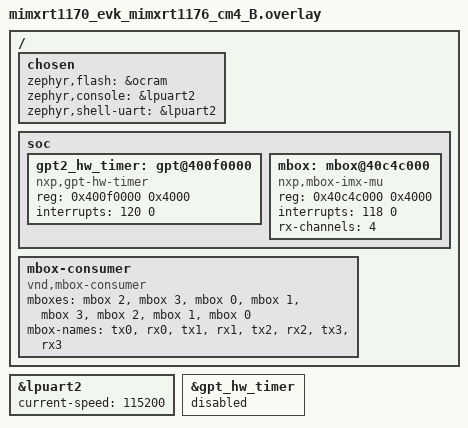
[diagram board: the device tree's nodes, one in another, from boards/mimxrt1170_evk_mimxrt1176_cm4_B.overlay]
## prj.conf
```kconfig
CONFIG_STDOUT_CONSOLE=n
CONFIG_MBOX=y
# CONFIG_NO_OPTIMIZATIONS=y
```

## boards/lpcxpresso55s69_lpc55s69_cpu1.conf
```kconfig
CONFIG_SECOND_CORE_MCUX=y
CONFIG_BUILD_OUTPUT_HEX=y
CONFIG_MBOX_NXP_MAILBOX=y
```

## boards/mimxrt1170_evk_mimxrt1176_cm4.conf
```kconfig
CONFIG_MBOX_NXP_IMX_MU=y
CONFIG_BUILD_OUTPUT_INFO_HEADER=y
CONFIG_BUILD_OUTPUT_HEX=y
CONFIG_SECOND_CORE_MCUX=y
```

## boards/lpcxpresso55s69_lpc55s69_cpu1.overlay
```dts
/*
 * Copyright 2024 NXP
 *
 * SPDX-License-Identifier: Apache-2.0
 */

/ {
	chosen {
		/* Delete ipc chosen property where old IPM mailbox driver bellow is
		 * configured.
		 */
		/delete-property/ zephyr,ipc;
	};

	soc {
		/* Delete IPM Driver node nxp,lpc-mailbox */
		/delete-node/ mailbox@8b000;

		/* Attach MBOX driver to Mailbox Unit */
		mbox:mbox@5008b000 {
			compatible = "nxp,mbox-mailbox";
			reg = <0x5008b000 0xEC>;
			interrupts = <31 0>;
			rx-channels = <4>;
			#mbox-cells = <1>;
			status = "okay";
		};
	};

	mbox-consumer {
		compatible = "vnd,mbox-consumer";
		mboxes = <&mbox 2>, <&mbox 3>, <&mbox 0>, <&mbox 1>, <&mbox 3>,
			 <&mbox 2>, <&mbox 1>, <&mbox 0>;
		mbox-names = "tx0", "rx0", "tx1", "rx1", "tx2", "rx2", "tx3",
			     "rx3";
	};
};
```

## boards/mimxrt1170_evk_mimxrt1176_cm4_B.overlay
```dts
/*
 * Copyright 2024 NXP
 *
 * SPDX-License-Identifier: Apache-2.0
 */

/ {
	chosen {
		zephyr,flash = &ocram;
		zephyr,console = &lpuart2;
		zephyr,shell-uart = &lpuart2;

		/* Delete ipc chosen property where old IPM mailbox driver bellow is
		 * configured.
		 */
		/delete-property/ zephyr,ipc;
	};

	soc {
		/delete-node/ gpt@400f0000;

		/* Replace GPT2 with another GPT kernel timer */
		gpt2_hw_timer:gpt@400f0000 {
			compatible = "nxp,gpt-hw-timer";
			reg = <0x400f0000 0x4000>;
			interrupts = <120 0>;
			status = "okay";
		};

		/* Delete IPM Driver node nxp,imx-mu */
		/delete-node/ mailbox@40c4c000;

		/* Attach MBOX driver to MU Unit */
		mbox:mbox@40c4c000 {
			compatible = "nxp,mbox-imx-mu";
			reg = <0x40c4c000 0x4000>;
			interrupts = <118 0>;
			rx-channels = <4>;
			#mbox-cells = <1>;
			status = "okay";
		};
	};

	mbox-consumer {
		compatible = "vnd,mbox-consumer";
		mboxes = <&mbox 2>, <&mbox 3>, <&mbox 0>, <&mbox 1>, <&mbox 3>,
			 <&mbox 2>, <&mbox 1>, <&mbox 0>;
		mbox-names = "tx0", "rx0", "tx1", "rx1", "tx2", "rx2", "tx3",
			     "rx3";
	};
};

/* Enable secondary LPUART */
&lpuart2 {
	status = "okay";
	current-speed = <115200>;
};

/* Disable primary GPT timer */
&gpt_hw_timer {
	status = "disabled";
};
```

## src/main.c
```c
/*
 * Copyright 2024 NXP
 *
 * SPDX-License-Identifier: Apache-2.0
 */

#include <stdio.h>
#include <stdlib.h>
#include <string.h>
#include <zephyr/kernel.h>
#include <zephyr/drivers/mbox.h>

static K_SEM_DEFINE(g_mbox_data_rx_sem, 0, 1);

static uint32_t g_mbox_received_data;
static uint32_t g_mbox_received_channel;

#define CHANNELS_TO_TEST 4
#define TX_CHANNEL_INDEX 0
#define RX_CHANNEL_INDEX 1

static const struct mbox_dt_spec channels[CHANNELS_TO_TEST][2] = {
	{
		MBOX_DT_SPEC_GET(DT_PATH(mbox_consumer), tx0),
		MBOX_DT_SPEC_GET(DT_PATH(mbox_consumer), rx0),
	},
	{
		MBOX_DT_SPEC_GET(DT_PATH(mbox_consumer), tx1),
		MBOX_DT_SPEC_GET(DT_PATH(mbox_consumer), rx1),
	},
	{
		MBOX_DT_SPEC_GET(DT_PATH(mbox_consumer), tx2),
		MBOX_DT_SPEC_GET(DT_PATH(mbox_consumer), rx2),
	},
	{
		MBOX_DT_SPEC_GET(DT_PATH(mbox_consumer), tx3),
		MBOX_DT_SPEC_GET(DT_PATH(mbox_consumer), rx3),
	},
};

static void callback(const struct device *dev, uint32_t channel, void *user_data,
		     struct mbox_msg *data)
{
	if (data != NULL) {
		memcpy(&g_mbox_received_data, data->data, data->size);
		g_mbox_received_channel = channel;
	}

	k_sem_give(&g_mbox_data_rx_sem);
}

int main(void)
{
	struct mbox_msg msg = {0};
	uint32_t message = 0;

	for (int i = 0; i < ARRAY_SIZE(channels); i++) {
		const struct mbox_dt_spec *tx_channel = &channels[i][TX_CHANNEL_INDEX];
		const struct mbox_dt_spec *rx_channel = &channels[i][RX_CHANNEL_INDEX];

		const int max_transfer_size_bytes = mbox_mtu_get_dt(tx_channel);
		/* Sample currently supports only transfer size up to 4 bytes */
		if ((max_transfer_size_bytes <= 0) || (max_transfer_size_bytes > 4)) {
			printk("mbox_mtu_get() error\n");
			return 0;
		}

		if (mbox_register_callback_dt(rx_channel, callback, NULL)) {
			printk("mbox_register_callback() error\n");
			return 0;
		}

		if (mbox_set_enabled_dt(rx_channel, 1)) {
			printk("mbox_set_enable() error\n");
			return 0;
		}

		int test_count = 0;

		while (test_count < 100) {
			test_count++;

			k_sem_take(&g_mbox_data_rx_sem, K_FOREVER);
			message = g_mbox_received_data;

			message++;

			msg.data = &message;
			msg.size = max_transfer_size_bytes;

			if (mbox_send_dt(tx_channel, &msg) < 0) {
				printk("mbox_send() error\n");
				return 0;
			}
		}

		/* Disable current rx channel after channel loop */
		mbox_set_enabled_dt(rx_channel, 0);
	}
}
```
